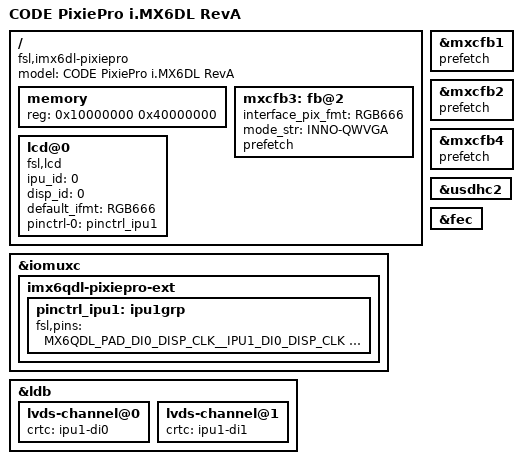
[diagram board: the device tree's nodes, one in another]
/*
 * Copyright (C) 2013 Freescale Semiconductor, Inc.
 *
 * This program is free software; you can redistribute it and/or modify
 * it under the terms of the GNU General Public License version 2 as
 * published by the Free Software Foundation.
 */

/dts-v1/;

#include "imx6dl.dtsi"
#include "imx6qdl-pixiepro.dtsi"

/ {
	model = "CODE PixiePro i.MX6DL RevA";
	compatible = "fsl,imx6dl-pixiepro", "fsl,imx6dl";

	memory: memory {
		reg = <0x10000000 0x40000000>;
	};

	mxcfb3: fb@2 {
		interface_pix_fmt = "RGB666";
		mode_str ="INNO-QWVGA";
	};

	lcd@0 {
		compatible = "fsl,lcd";
		ipu_id = <0>;
		disp_id = <0>;
		default_ifmt = "RGB666";
		pinctrl-names = "default";
		pinctrl-0 = <&pinctrl_ipu1>;
		status = "okay";
	};	

};

&iomuxc {
	pinctrl-names = "default";

	imx6qdl-pixiepro-ext {

		pinctrl_ipu1: ipu1grp {
			fsl,pins = <
				MX6QDL_PAD_DI0_DISP_CLK__IPU1_DI0_DISP_CLK 0x10
				MX6QDL_PAD_DI0_PIN15__IPU1_DI0_PIN15       0x10
				MX6QDL_PAD_DI0_PIN2__IPU1_DI0_PIN02        0x10
				MX6QDL_PAD_DI0_PIN3__IPU1_DI0_PIN03        0x10
				MX6QDL_PAD_DI0_PIN4__IPU1_DI0_PIN04        0x80000000
				MX6QDL_PAD_DISP0_DAT0__IPU1_DISP0_DATA00   0x10
				MX6QDL_PAD_DISP0_DAT1__IPU1_DISP0_DATA01   0x10
				MX6QDL_PAD_DISP0_DAT2__IPU1_DISP0_DATA02   0x10
				MX6QDL_PAD_DISP0_DAT3__IPU1_DISP0_DATA03   0x10
				MX6QDL_PAD_DISP0_DAT4__IPU1_DISP0_DATA04   0x10
				MX6QDL_PAD_DISP0_DAT5__IPU1_DISP0_DATA05   0x10
				MX6QDL_PAD_DISP0_DAT6__IPU1_DISP0_DATA06   0x10
				MX6QDL_PAD_DISP0_DAT7__IPU1_DISP0_DATA07   0x10
				MX6QDL_PAD_DISP0_DAT8__IPU1_DISP0_DATA08   0x10
				MX6QDL_PAD_DISP0_DAT9__IPU1_DISP0_DATA09   0x10
				MX6QDL_PAD_DISP0_DAT10__IPU1_DISP0_DATA10  0x10
				MX6QDL_PAD_DISP0_DAT11__IPU1_DISP0_DATA11  0x10
				MX6QDL_PAD_DISP0_DAT12__IPU1_DISP0_DATA12  0x10
				MX6QDL_PAD_DISP0_DAT13__IPU1_DISP0_DATA13  0x10
				MX6QDL_PAD_DISP0_DAT14__IPU1_DISP0_DATA14  0x10
				MX6QDL_PAD_DISP0_DAT15__IPU1_DISP0_DATA15  0x10
				MX6QDL_PAD_DISP0_DAT16__IPU1_DISP0_DATA16  0x10
				MX6QDL_PAD_DISP0_DAT17__IPU1_DISP0_DATA17  0x10
			>;
		};
	};
};

&ldb {
	lvds-channel@0 {
		crtc = "ipu1-di0";
	};
	lvds-channel@1 {
		crtc = "ipu1-di1";
	};
};

&mxcfb1 {
	prefetch;
	status = "okay";
};

&mxcfb2 {
	prefetch;
	status = "okay";
};

&mxcfb3 {
	prefetch;
	status = "okay";
};

&mxcfb4 {
	prefetch;
	status = "okay";
};

&usdhc2 {
	status = "okay";
};

&fec {
	status = "okay";
};
